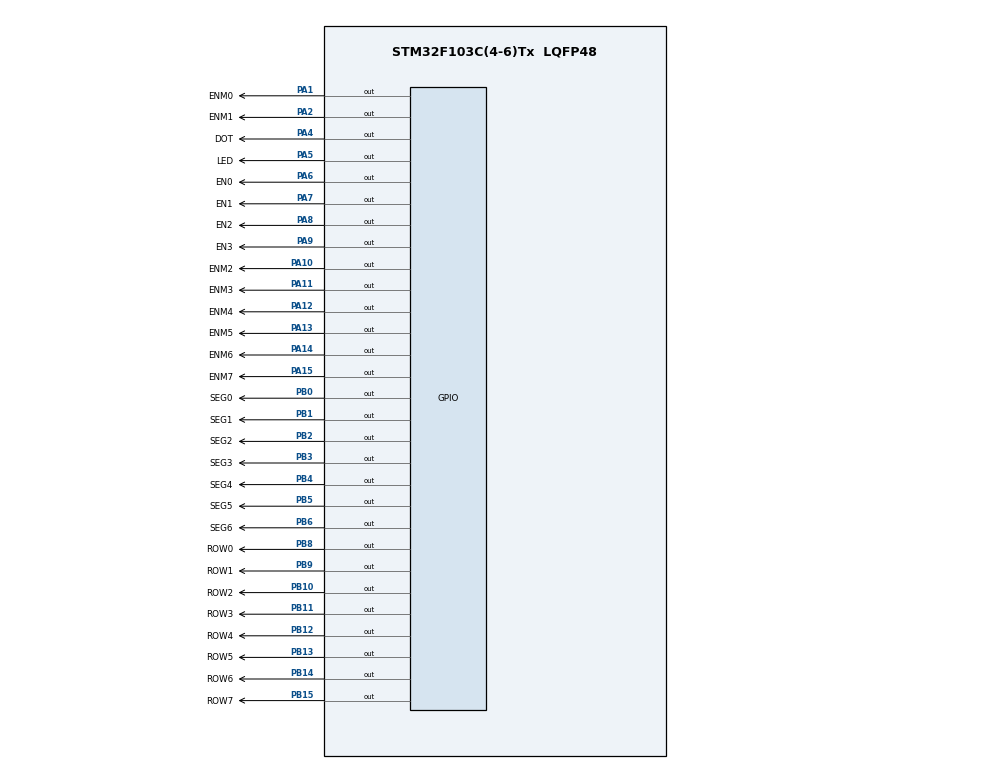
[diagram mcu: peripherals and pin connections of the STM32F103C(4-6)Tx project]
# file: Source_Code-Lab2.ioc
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Mcu.Family=STM32F1
Mcu.Name=STM32F103C(4-6)Tx
Mcu.Package=LQFP48
NVIC.PriorityGroup=NVIC_PRIORITYGROUP_4
NVIC.TIM2_IRQn=true\:0\:0\:false\:false\:true\:true\:true
PA1.GPIO_Label=ENM0
PA1.Signal=GPIO_Output
PA10.GPIO_Label=ENM2
PA10.Signal=GPIO_Output
PA11.GPIO_Label=ENM3
PA11.Signal=GPIO_Output
PA12.GPIO_Label=ENM4
PA12.Signal=GPIO_Output
PA13.GPIO_Label=ENM5
PA13.Signal=GPIO_Output
PA14.GPIO_Label=ENM6
PA14.Signal=GPIO_Output
PA15.GPIO_Label=ENM7
PA15.Signal=GPIO_Output
PA2.GPIO_Label=ENM1
PA2.Signal=GPIO_Output
PA4.GPIO_Label=DOT
PA4.Signal=GPIO_Output
PA5.GPIO_Label=LED
PA5.Signal=GPIO_Output
PA6.GPIO_Label=EN0
PA6.Signal=GPIO_Output
PA7.GPIO_Label=EN1
PA7.Signal=GPIO_Output
PA8.GPIO_Label=EN2
PA8.Signal=GPIO_Output
PA9.GPIO_Label=EN3
PA9.Signal=GPIO_Output
PB0.GPIO_Label=SEG0
PB0.Signal=GPIO_Output
PB1.GPIO_Label=SEG1
PB1.Signal=GPIO_Output
PB10.GPIO_Label=ROW2
PB10.Signal=GPIO_Output
PB11.GPIO_Label=ROW3
PB11.Signal=GPIO_Output
PB12.GPIO_Label=ROW4
PB12.Signal=GPIO_Output
PB13.GPIO_Label=ROW5
PB13.Signal=GPIO_Output
PB14.GPIO_Label=ROW6
PB14.Signal=GPIO_Output
PB15.GPIO_Label=ROW7
PB15.Signal=GPIO_Output
PB2.GPIO_Label=SEG2
PB2.Signal=GPIO_Output
PB3.GPIO_Label=SEG3
PB3.Signal=GPIO_Output
PB4.GPIO_Label=SEG4
PB4.Signal=GPIO_Output
PB5.GPIO_Label=SEG5
PB5.Signal=GPIO_Output
PB6.GPIO_Label=SEG6
PB6.Signal=GPIO_Output
PB8.GPIO_Label=ROW0
PB8.Signal=GPIO_Output
PB9.GPIO_Label=ROW1
PB9.Signal=GPIO_Output
ProjectManager.HeapSize=0x200
ProjectManager.StackSize=0x400
ProjectManager.TargetToolchain=STM32CubeIDE
RCC.APB1Freq_Value=8000000
RCC.APB2Freq_Value=8000000
TIM2.Period=9
TIM2.Prescaler=7999
VP_SYS_VS_ND.Mode=No_Debug
VP_TIM2_VS_ClockSourceINT.Mode=Internal
board=custom

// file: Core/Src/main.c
/* USER CODE BEGIN Header */
/**
  ******************************************************************************
  * @file           : main.c
  * @brief          : Main program body
  ******************************************************************************
  * @attention
  *
  * <h2><center>&copy; Copyright (c) 2025 STMicroelectronics.
  * All rights reserved.</center></h2>
  *
  * This software component is licensed by ST under BSD 3-Clause license,
  * the "License"; You may not use this file except in compliance with the
  * License. You may obtain a copy of the License at:
  *                        opensource.org/licenses/BSD-3-Clause
  *
  ******************************************************************************
  */
/* USER CODE END Header */
#include "main.h"

/* USER CODE BEGIN PD */
#define TIME_CYCLE 10;
/* USER CODE END PD */

TIM_HandleTypeDef htim2;

/* USER CODE BEGIN PV */
const uint8_t segment_code[7] = {0x01, 0x02, 0x04, 0x08, 0x10, 0x20, 0x40}; //a->g
const uint8_t number_code[10] = {0x3F, 0x06, 0x5B, 0x4F, 0x66, 0x6D, 0x7D, 0x07, 0x7F, 0x6F};	//0->9 a->g
int led_buffer[4] = {1, 5, 0, 8};

int hour = 15 , minute = 8 , second = 50;

int led_counter = 100;
int seg_counter = 25;
int seg_state = 1;		//Init already called seg_state = 0;

int timer0_counter = 0;
int timer0_flag = 0;

int timer1_counter = 0;
int timer1_flag = 0;

/* USER CODE END PV */

void SystemClock_Config(void);
static void MX_GPIO_Init(void);
static void MX_TIM2_Init(void);
/* USER CODE BEGIN PFP */
void Clear7SEG();

void ClearEnState7SEG();
void WriteEnState7SEG(int number);
void FillEnState7SEG();

void Display7SEG(int number);
void update7SEG(int index);
void updateClockBuffer();

void setTimer0(int duration);
void runTimer0();

void setTimer1(int duration);
void runTimer1();

/* USER CODE END PFP */

/* USER CODE BEGIN 0 */
void Display7SEG(int number){
	Clear7SEG();

	HAL_GPIO_WritePin(GPIOB, SEG0_Pin << 0, !(segment_code[0] & number_code[number]));
	HAL_GPIO_WritePin(GPIOB, SEG0_Pin << 1, !(segment_code[1] & number_code[number]));
	HAL_GPIO_WritePin(GPIOB, SEG0_Pin << 2, !(segment_code[2] & number_code[number]));
	HAL_GPIO_WritePin(GPIOB, SEG0_Pin << 3, !(segment_code[3] & number_code[number]));
	HAL_GPIO_WritePin(GPIOB, SEG0_Pin << 4, !(segment_code[4] & number_code[number]));
	HAL_GPIO_WritePin(GPIOB, SEG0_Pin << 5, !(segment_code[5] & number_code[number]));
	HAL_GPIO_WritePin(GPIOB, SEG0_Pin << 6, !(segment_code[6] & number_code[number]));
}

void Clear7SEG(){
	HAL_GPIO_WritePin(GPIOB, SEG0_Pin << 0, SET);
	HAL_GPIO_WritePin(GPIOB, SEG0_Pin << 1, SET);
	HAL_GPIO_WritePin(GPIOB, SEG0_Pin << 2, SET);
	HAL_GPIO_WritePin(GPIOB, SEG0_Pin << 3, SET);
	HAL_GPIO_WritePin(GPIOB, SEG0_Pin << 4, SET);
	HAL_GPIO_WritePin(GPIOB, SEG0_Pin << 5, SET);
	HAL_GPIO_WritePin(GPIOB, SEG0_Pin << 6, SET);
}

void WriteEnState7SEG(int number){
	ClearEnState7SEG();
	if(number >= 0){
		HAL_GPIO_WritePin(GPIOA, EN0_Pin << number, RESET);
	}
}

void ClearEnState7SEG(){
	//This will be updated as more 7-segment display is included
	HAL_GPIO_WritePin(GPIOA, EN0_Pin << 0, SET);
	HAL_GPIO_WritePin(GPIOA, EN0_Pin << 1, SET);
	HAL_GPIO_WritePin(GPIOA, EN0_Pin << 2, SET);
	HAL_GPIO_WritePin(GPIOA, EN0_Pin << 3, SET);
}

void FillEnState7SEG(){
	HAL_GPIO_WritePin(GPIOA, EN0_Pin << 0, RESET);
	HAL_GPIO_WritePin(GPIOA, EN0_Pin << 1, RESET);
	HAL_GPIO_WritePin(GPIOA, EN0_Pin << 2, RESET);
	HAL_GPIO_WritePin(GPIOA, EN0_Pin << 3, RESET);
}

void update7SEG(int index){
	WriteEnState7SEG(index);
	switch(index){
	case 0:
		Display7SEG(led_buffer[0]);
		break;

	case 1:
		Display7SEG(led_buffer[1]);
		break;

	case 2:
		Display7SEG(led_buffer[2]);
		break;

	case 3:
		Display7SEG(led_buffer[3]);
		break;

	default:
		break;
	}
}

void updateClockBuffer(){
	led_buffer[0] = hour / 10;
	led_buffer[1] = hour - led_buffer[0] * 10;
	led_buffer[2] = minute / 10;
	led_buffer[3] = minute - led_buffer[2] * 10;
};

void setTimer0(int duration){
	timer0_counter = duration / TIME_CYCLE;
	timer0_flag = 0;
}

void runTimer0(){
	if(timer0_counter > 0){
		--timer0_counter;
		if(timer0_counter <= 0){
			timer0_flag = 1;
		}
	}
}

void setTimer1(int duration){
	timer1_counter = duration / TIME_CYCLE;
	timer1_flag = 0;
}

void runTimer1(){
	if(timer1_counter > 0){
		--timer1_counter;
		if(timer1_counter <= 0){
			timer1_flag = 1;
		}
	}
}

/* USER CODE END 0 */

int main(void)
{

  /* MCU Configuration--------------------------------------------------------*/

  /* Reset of all peripherals, Initializes the Flash interface and the Systick. */
  HAL_Init();

  /* Configure the system clock */
  SystemClock_Config();

  /* Initialize all configured peripherals */
  MX_GPIO_Init();
  MX_TIM2_Init();
  /* USER CODE BEGIN 2 */
  HAL_TIM_Base_Start_IT(&htim2);

  //Segment start with EN0
  Display7SEG(led_buffer[0]);
  WriteEnState7SEG(0);
  setTimer0(1000);
  setTimer1(1000);
  /* USER CODE END 2 */

  /* Infinite loop */
  while (1)
  {

    /* USER CODE BEGIN 3 */

	  if(second >= 60){
		  minute++;
		  second = 0;
	  }

	  if(minute >= 60){
		  hour++;
		  minute = 0;
	  }

	  if(hour >= 24){
		  hour = 0;
	  }

	  if(timer0_flag == 1){
		  HAL_GPIO_TogglePin(LED_GPIO_Port, LED_Pin);
		  HAL_GPIO_TogglePin(DOT_GPIO_Port, DOT_Pin);
		  updateClockBuffer();
		  setTimer0(1000);
		  second++;
	  }
  }
  /* USER CODE END 3 */
}

void SystemClock_Config(void)
{
  RCC_OscInitTypeDef RCC_OscInitStruct = {0};
  RCC_ClkInitTypeDef RCC_ClkInitStruct = {0};

  /** Initializes the RCC Oscillators according to the specified parameters
  * in the RCC_OscInitTypeDef structure.
  */
  RCC_OscInitStruct.OscillatorType = RCC_OSCILLATORTYPE_HSI;
  RCC_OscInitStruct.HSIState = RCC_HSI_ON;
  RCC_OscInitStruct.HSICalibrationValue = RCC_HSICALIBRATION_DEFAULT;
  RCC_OscInitStruct.PLL.PLLState = RCC_PLL_NONE;
  if (HAL_RCC_OscConfig(&RCC_OscInitStruct) != HAL_OK)
  {
    Error_Handler();
  }
  /** Initializes the CPU, AHB and APB buses clocks
  */
  RCC_ClkInitStruct.ClockType = RCC_CLOCKTYPE_HCLK|RCC_CLOCKTYPE_SYSCLK
                              |RCC_CLOCKTYPE_PCLK1|RCC_CLOCKTYPE_PCLK2;
  RCC_ClkInitStruct.SYSCLKSource = RCC_SYSCLKSOURCE_HSI;
  RCC_ClkInitStruct.AHBCLKDivider = RCC_SYSCLK_DIV1;
  RCC_ClkInitStruct.APB1CLKDivider = RCC_HCLK_DIV1;
  RCC_ClkInitStruct.APB2CLKDivider = RCC_HCLK_DIV1;

  if (HAL_RCC_ClockConfig(&RCC_ClkInitStruct, FLASH_LATENCY_0) != HAL_OK)
  {
    Error_Handler();
  }
}

static void MX_TIM2_Init(void)
{

  TIM_ClockConfigTypeDef sClockSourceConfig = {0};
  TIM_MasterConfigTypeDef sMasterConfig = {0};

  htim2.Instance = TIM2;
  htim2.Init.Prescaler = 7999;
  htim2.Init.CounterMode = TIM_COUNTERMODE_UP;
  htim2.Init.Period = 9;
  htim2.Init.ClockDivision = TIM_CLOCKDIVISION_DIV1;
  htim2.Init.AutoReloadPreload = TIM_AUTORELOAD_PRELOAD_DISABLE;
  if (HAL_TIM_Base_Init(&htim2) != HAL_OK)
  {
    Error_Handler();
  }
  sClockSourceConfig.ClockSource = TIM_CLOCKSOURCE_INTERNAL;
  if (HAL_TIM_ConfigClockSource(&htim2, &sClockSourceConfig) != HAL_OK)
  {
    Error_Handler();
  }
  sMasterConfig.MasterOutputTrigger = TIM_TRGO_RESET;
  sMasterConfig.MasterSlaveMode = TIM_MASTERSLAVEMODE_DISABLE;
  if (HAL_TIMEx_MasterConfigSynchronization(&htim2, &sMasterConfig) != HAL_OK)
  {
    Error_Handler();
  }

}

static void MX_GPIO_Init(void)
{
  GPIO_InitTypeDef GPIO_InitStruct = {0};

  /* GPIO Ports Clock Enable */
  __HAL_RCC_GPIOA_CLK_ENABLE();
  __HAL_RCC_GPIOB_CLK_ENABLE();

  /*Configure GPIO pin Output Level */
  HAL_GPIO_WritePin(GPIOA, DOT_Pin|LED_Pin|EN0_Pin|EN1_Pin
                          |EN3_Pin|EN4_Pin, GPIO_PIN_RESET);

  /*Configure GPIO pin Output Level */
  HAL_GPIO_WritePin(GPIOB, SEG0_Pin|SEG1_Pin|SEG2_Pin|SEG3_Pin
                          |SEG4_Pin|SEG5_Pin|SEG6_Pin, GPIO_PIN_RESET);

  /*Configure GPIO pins : DOT_Pin LED_Pin EN0_Pin EN1_Pin
                           EN3_Pin EN4_Pin */
  GPIO_InitStruct.Pin = DOT_Pin|LED_Pin|EN0_Pin|EN1_Pin
                          |EN3_Pin|EN4_Pin;
  GPIO_InitStruct.Mode = GPIO_MODE_OUTPUT_PP;
  GPIO_InitStruct.Pull = GPIO_NOPULL;
  GPIO_InitStruct.Speed = GPIO_SPEED_FREQ_LOW;
  HAL_GPIO_Init(GPIOA, &GPIO_InitStruct);

  /*Configure GPIO pins : SEG0_Pin SEG1_Pin SEG2_Pin SEG3_Pin
                           SEG4_Pin SEG5_Pin SEG6_Pin */
  GPIO_InitStruct.Pin = SEG0_Pin|SEG1_Pin|SEG2_Pin|SEG3_Pin
                          |SEG4_Pin|SEG5_Pin|SEG6_Pin;
  GPIO_InitStruct.Mode = GPIO_MODE_OUTPUT_PP;
  GPIO_InitStruct.Pull = GPIO_NOPULL;
  GPIO_InitStruct.Speed = GPIO_SPEED_FREQ_LOW;
  HAL_GPIO_Init(GPIOB, &GPIO_InitStruct);

}

/* USER CODE BEGIN 4 */
void HAL_TIM_PeriodElapsedCallback ( TIM_HandleTypeDef * htim ){
	--seg_counter;
	if(seg_counter <= 0){
		seg_counter = 25;
		update7SEG(seg_state++);
		if(seg_state >= 4){
			seg_state = 0;
		}

	}

	runTimer0();
	runTimer1();
}
/* USER CODE END 4 */

void Error_Handler(void)
{
  __disable_irq();
  while (1)
  {
  }
}

/************************ (C) COPYRIGHT STMicroelectronics *****END OF FILE****/
